# S6E1B8xE register map
Vendor: Cypress; File version: 2.1
CPU: CM0PLUS r0p1, little endian, no MPU, no FPU, 2 interrupt priority bits
Registers are 8-bit, read-write, reset 0x0 unless marked. A register's access mark holds for its fields unless they carry their own. Offsets are from the block's base; [hi:lo] are bit positions; {n}, {i} and the like mark numbered series.

## INTREQ — Interrupts
Base 0x40031000
0x0C IRQCMODE 32-bit — Interrupt Factor Vector Relocate Setting Register [BHW]
  [0] IRQCMODE — Select an interrupt factor vector. See peripheral manual for detials
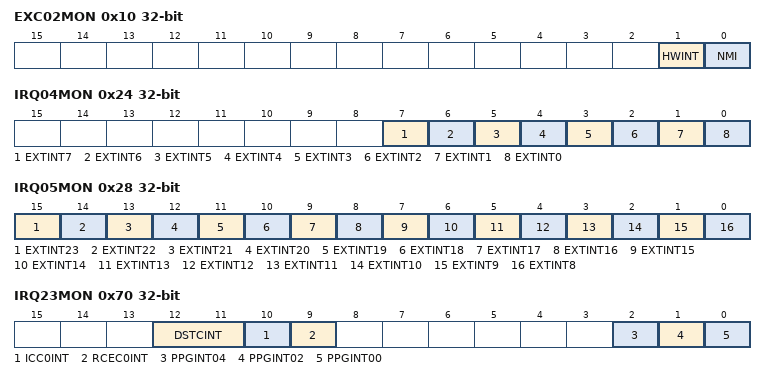
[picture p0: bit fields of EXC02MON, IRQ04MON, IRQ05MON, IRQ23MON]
0x10 EXC02MON 32-bit ro — EXC02 Batch Read Register [BHW]
  [1] HWINT — Hardware watchdog timer interrupt request
  [0] NMI — NMIX external pin interrupt request
0x14 IRQ00MON 32-bit ro — IRQ00 Batch Read Register [BHW]
  [0] FCSINT — Anomalous frequency detection by CSV interrupt request
0x18 IRQ01MON 32-bit ro — IRQ01 Batch Read Register [BHW]
  [0] SWWDTINT — Software watchdog timer interrupt request
0x1C IRQ02MON 32-bit ro — IRQ02 Batch Read Register [BHW]
  [0] LVDINT — Low voltage detection (LVD) interrupt request
0x20 IRQ03MON 32-bit ro — IRQ03 Batch Read Register [BHW]
  [3:0] WAVE0INT — WFG timer or DTIF interrupt requests in MFT unit 0
0x24 IRQ04MON 32-bit ro — IRQ04 Batch Read Register [BHW]
  [7] EXTINT7 — Interrupt request of external interrupt ch.7
  [6] EXTINT6 — Interrupt request of external interrupt ch.6
  [5] EXTINT5 — Interrupt request of external interrupt ch.5
  [4] EXTINT4 — Interrupt request of external interrupt ch.4
  [3] EXTINT3 — Interrupt request of external interrupt ch.3
  [2] EXTINT2 — Interrupt request of external interrupt ch.2
  [1] EXTINT1 — Interrupt request of external interrupt ch.1
  [0] EXTINT0 — Interrupt request of external interrupt ch.0
0x28 IRQ05MON 32-bit ro — IRQ05 Batch Read Register [BHW]
  [15] EXTINT23 — Interrupt request of external interrupt ch.23
  [14] EXTINT22 — Interrupt request of external interrupt ch.22
  [13] EXTINT21 — Interrupt request of external interrupt ch.21
  [12] EXTINT20 — Interrupt request of external interrupt ch.20
  [11] EXTINT19 — Interrupt request of external interrupt ch.19
  [10] EXTINT18 — Interrupt request of external interrupt ch.18
  [9] EXTINT17 — Interrupt request of external interrupt ch.17
  [8] EXTINT16 — Interrupt request of external interrupt ch.16
  [7] EXTINT15 — Interrupt request of external interrupt ch.15
  [6] EXTINT14 — Interrupt request of external interrupt ch.14
  [5] EXTINT13 — Interrupt request of external interrupt ch.13
  [4] EXTINT12 — Interrupt request of external interrupt ch.12
  [3] EXTINT11 — Interrupt request of external interrupt ch.11
  [2] EXTINT10 — Interrupt request of external interrupt ch.10
  [1] EXTINT9 — Interrupt request of external interrupt ch.9
  [0] EXTINT8 — Interrupt request of external interrupt ch.8
0x2C IRQ06MON 32-bit ro — IRQ06 Batch Read Register [BHW]
  [1:0] TIMINT — Dual timer interrupt request
0x30 IRQ07MON 32-bit ro — IRQ07 Batch Read Register [BHW]
  [0] MFSINT — Reception interrupt request of MFS channel 0
0x34 IRQ08MON 32-bit ro — IRQ08 Batch Read Register [BHW]
  [1:0] MFSINT — Status/Transmission interrupt request of MFS channel 0
0x38 IRQ09MON 32-bit ro — IRQ09 Batch Read Register [BHW]
  [0] MFSINT — Reception interrupt request of MFS channel 1
0x3C IRQ10MON 32-bit ro — IRQ10 Batch Read Register [BHW]
  [1:0] MFSINT — Status/Transmission interrupt request of MFS channel 1
0x40 IRQ11MON 32-bit ro — IRQ11 Batch Read Register [BHW]
  [0] MFSINT — Reception interrupt request of MFS channel 2
0x44 IRQ12MON 32-bit ro — IRQ12 Batch Read Register [BHW]
  [1:0] MFSINT — Status/Transmission interrupt request of MFS channel 2
0x48 IRQ13MON 32-bit ro — IRQ13 Batch Read Register [BHW]
  [0] MFSINT — Reception interrupt request of MFS channel 3
0x4C IRQ14MON 32-bit ro — IRQ14 Batch Read Register [BHW]
  [1:0] MFSINT — Status/Transmission interrupt request of MFS channel 3
0x50 IRQ15MON 32-bit ro — IRQ15 Batch Read Register [BHW]
  [0] MFSINT — Reception interrupt request of MFS channel 4
0x54 IRQ16MON 32-bit ro — IRQ16 Batch Read Register [BHW]
  [1:0] MFSINT — Status/Transmission interrupt request of MFS channel 4
0x58 IRQ17MON 32-bit ro — IRQ17 Batch Read Register [BHW]
  [0] MFSINT — Reception interrupt request of MFS channel 5
0x5C IRQ18MON 32-bit ro — IRQ18 Batch Read Register [BHW]
  [1:0] MFSINT — Status/Transmission interrupt request of MFS channel 5
0x60 IRQ19MON 32-bit ro — IRQ19 Batch Read Register [BHW]
  [0] MFSINT — Reception interrupt request of MFS channel 6
0x64 IRQ20MON 32-bit ro — IRQ20 Batch Read Register [BHW]
  [1:0] MFSINT — Status/Transmission interrupt request of MFS channel 6
0x68 IRQ21MON 32-bit ro — IRQ21 Batch Read Register [BHW]
  [0] MFSINT — Reception interrupt request of MFS channel 7
0x6C IRQ22MON 32-bit ro — IRQ22 Batch Read Register [BHW]
  [1:0] MFSINT — Status/Transmission interrupt request of MFS channel 7
0x70 IRQ23MON 32-bit ro — IRQ23 Batch Read Register [BHW]
  [12:11] DSTCINT — Interrupt request of DSTC ERINT
  [10] ICC0INT — Interrupt request of IC card (smart card interface) ch.0
  [9] RCEC0INT — Interrupt request of HDMI-CEC remport control reception ch.0
  [2] PPGINT04 — Interrupt request of PPG ch.4
  [1] PPGINT02 — Interrupt request of PPG ch.2
  [0] PPGINT00 — Interrupt request of PPG ch.0
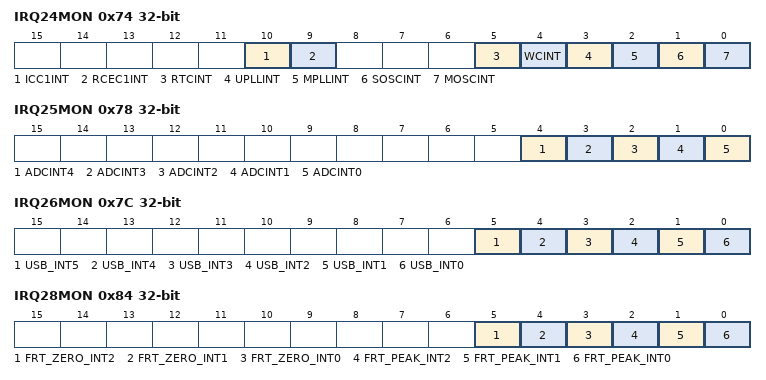
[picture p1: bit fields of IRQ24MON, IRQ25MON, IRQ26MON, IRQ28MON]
0x74 IRQ24MON 32-bit ro — IRQ24 Batch Read Register [BHW]
  [10] ICC1INT — Interrupt request of IC card (smart card interface) ch.1
  [9] RCEC1INT — Interrupt request of HDMI-CEC remport control reception ch.1
  [5] RTCINT — RTC interrupt request
  [4] WCINT — Watch counter interrupt request
  [3] UPLLINT — Stabilization wait completion interrupt request for USB oscillation
  [2] MPLLINT — Stabilization wait completion interrupt request for main PLL oscillation
  [1] SOSCINT — Stabilization wait completion interrupt request for sub-clock oscillation
  [0] MOSCINT — Stabilization wait completion interrupt request for main clock oscillation
0x78 IRQ25MON 32-bit ro — IRQ25 Batch Read Register [BHW]
  [4] ADCINT4 — Range comparison result interrupt request in the A/D converter unit 0
  [3] ADCINT3 — Conversion result comparison interrupt request in the A/D converter unit 0
  [2] ADCINT2 — FIFO overrun interrupt request in the A/D converter unit 0
  [1] ADCINT1 — Scan conversion interrupt request in the A/D converter unit 0
  [0] ADCINT0 — Priority conversion interrupt request in the A/D converter unit 0
0x7C IRQ26MON 32-bit ro — IRQ26 Batch Read Register [BHW]
  [5] USB_INT5 — SOFIRQ/CMPIRQ interrupt request of USB ch.0
  [4] USB_INT4 — DIRQ/URIRQ/RWKIRQ/CNNIRQ interrupt request of USB ch.0
  [3] USB_INT3 — SPK interrupt request of USB ch.0
  [2] USB_INT2 — SUSP/SOF/BRST/CONF/WKUP interrupt request of USB ch.0
  [1] USB_INT1 — Endpoint0 DRQO interrupt request of USB ch.0
  [0] USB_INT0 — Endpoint0 DRQI interrupt request of USB ch.0
0x80 IRQ27MON 32-bit ro — IRQ27 Batch Read Register [BHW]
  [5] LCDCINT — Interrupt request for LCD controller
0x84 IRQ28MON 32-bit ro — IRQ28 Batch Read Register [BHW]
  [5] FRT_ZERO_INT2 — Zero detection interrupt request of the free run timer ch.2 in the MFT unit 0
  [4] FRT_ZERO_INT1 — Zero detection interrupt request of the free run timer ch.1 in the MFT unit 0
  [3] FRT_ZERO_INT0 — Zero detection interrupt request of the free run timer ch.0 in the MFT unit 0
  [2] FRT_PEAK_INT2 — Peak value detection interrupt request of the free run timer ch.2 in the MFT unit 0
  [1] FRT_PEAK_INT1 — Peak value detection interrupt request of the free run timer ch.1 in the MFT unit 0
  [0] FRT_PEAK_INT0 — Peak value detection interrupt request of the free run timer ch.0 in the MFT unit 0
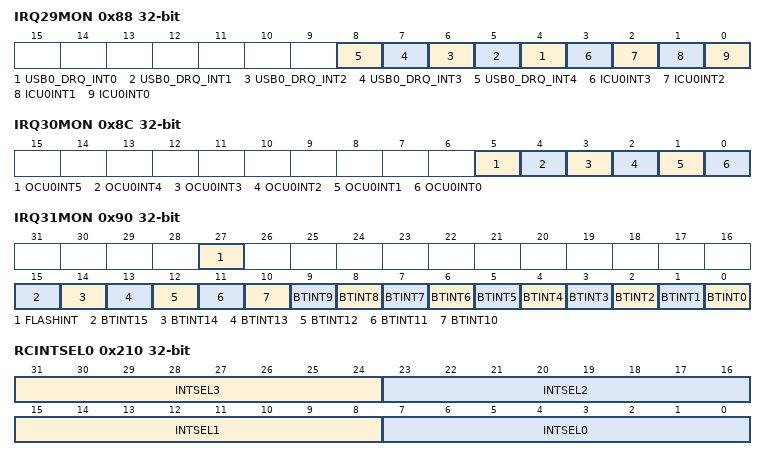
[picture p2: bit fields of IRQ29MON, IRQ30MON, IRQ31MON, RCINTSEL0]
0x88 IRQ29MON 32-bit ro — IRQ29 Batch Read Register [BHW]
  [n+4] USB0_DRQ_INT{n} (n=0..4) — Endpoint{n+1} DRQO interrupt request of USB ch.0
  [3] ICU0INT3 — Interrupt request of the input capture ch.3 in the MFT unit 0
  [2] ICU0INT2 — Interrupt request of the input capture ch.2 in the MFT unit 0
  [1] ICU0INT1 — Interrupt request of the input capture ch.1 in the MFT unit 0
  [0] ICU0INT0 — Interrupt request of the input capture ch.0 in the MFT unit 0
0x8C IRQ30MON 32-bit ro — IRQ30 Batch Read Register [BHW]
  [5] OCU0INT5 — Interrupt request of the output compare ch.5 in the MFT unit 0
  [4] OCU0INT4 — Interrupt request of the output compare ch.4 in the MFT unit 0
  [3] OCU0INT3 — Interrupt request of the output compare ch.3 in the MFT unit 0
  [2] OCU0INT2 — Interrupt request of the output compare ch.2 in the MFT unit 0
  [1] OCU0INT1 — Interrupt request of the output compare ch.1 in the MFT unit 0
  [0] OCU0INT0 — Interrupt request of the output compare ch.0 in the MFT unit 0
0x90 IRQ31MON 32-bit ro — IRQ31 Batch Read Register [BHW]
  [27] FLASHINT — RDY/HANG interrupt request for f lash memory
  [15] BTINT15 — IRQ1 interrupt request of the base timer ch.7
  [14] BTINT14 — IRQ0 interrupt request of the base timer ch.7
  [13] BTINT13 — IRQ1 interrupt request of the base timer ch.6
  [12] BTINT12 — IRQ0 interrupt request of the base timer ch.6
  [11] BTINT11 — IRQ1 interrupt request of the base timer ch.5
  [10] BTINT10 — IRQ0 interrupt request of the base timer ch.5
  [9] BTINT9 — IRQ1 interrupt request of the base timer ch.4
  [8] BTINT8 — IRQ0 interrupt request of the base timer ch.4
  [7] BTINT7 — IRQ1 interrupt request of the base timer ch.3
  [6] BTINT6 — IRQ0 interrupt request of the base timer ch.3
  [5] BTINT5 — IRQ1 interrupt request of the base timer ch.2
  [4] BTINT4 — IRQ0 interrupt request of the base timer ch.2
  [3] BTINT3 — IRQ1 interrupt request of the base timer ch.1
  [2] BTINT2 — IRQ0 interrupt request of the base timer ch.1
  [1] BTINT1 — IRQ1 interrupt request of the base timer ch.0
  [0] BTINT0 — IRQ0 interrupt request of the base timer ch.0
0x210 RCINTSEL0 32-bit — Interrupt Factor Selection Register 0 [BHW]
  [31:24] INTSEL3 — Select the interrupt factor for the interrupt vector No.22
  [23:16] INTSEL2 — Select the interrupt factor for the interrupt vector No.21
  [15:8] INTSEL1 — Select the interrupt factor for the interrupt vector No.20
  [7:0] INTSEL0 — Select the interrupt factor for the interrupt vector No.19
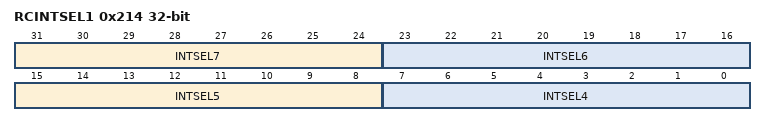
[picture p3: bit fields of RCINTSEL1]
0x214 RCINTSEL1 32-bit — Interrupt Factor Selection Register 1 [BHW]
  [31:24] INTSEL7 — Select the interrupt factor for the interrupt vector No.26
  [23:16] INTSEL6 — Select the interrupt factor for the interrupt vector No.25
  [15:8] INTSEL5 — Select the interrupt factor for the interrupt vector No.24
  [7:0] INTSEL4 — Select the interrupt factor for the interrupt vector No.23
